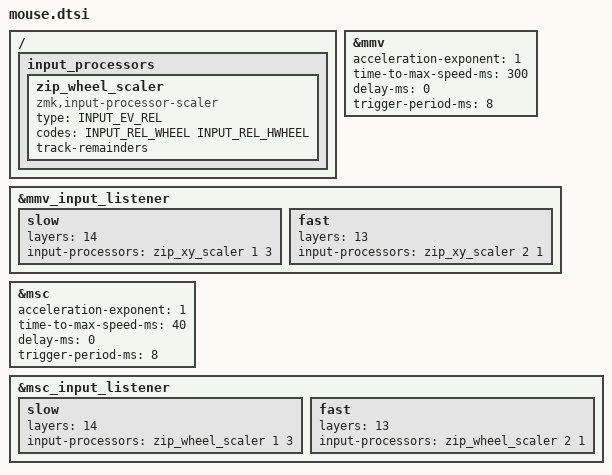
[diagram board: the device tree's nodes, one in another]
#define ZMK_POINTING_DEFAULT_MOVE_VAL 800  // 600
#define ZMK_POINTING_DEFAULT_SCRL_VAL 20   // 10

#include <dt-bindings/zmk/pointing.h>
#include <input/processors.dtsi>
#include <zephyr/dt-bindings/input/input-event-codes.h>

/ {
    input_processors {
        zip_wheel_scaler: zip_wheel_scaler {
            compatible = "zmk,input-processor-scaler";
            #input-processor-cells = <2>;
            type = <INPUT_EV_REL>;
            codes = <INPUT_REL_WHEEL INPUT_REL_HWHEEL>;
            track-remainders;
        };
    };
};

&mmv {
    acceleration-exponent = <1>;  // 1
    time-to-max-speed-ms = <300>; // 300
    delay-ms = <0>;
    trigger-period-ms = <8>;      // 16
};
&mmv_input_listener {
    slow {
        layers = <14>;
        input-processors = <&zip_xy_scaler 1 3>;
    };
    fast {
        layers = <13>;
        input-processors = <&zip_xy_scaler 2 1>;
    };
};

&msc {
    acceleration-exponent = <1>;  // 0
    time-to-max-speed-ms = <40>;  // 300
    delay-ms = <0>;
    trigger-period-ms = <8>;      // 16
};
&msc_input_listener {
    slow {
        layers = <14>;
        input-processors = <&zip_wheel_scaler 1 3>;
    };
    fast {
        layers = <13>;
        input-processors = <&zip_wheel_scaler 2 1>;
    };
};
